# GD32A503 register map
File version: 1.0
GD32A503 ARM 32-bit Cortex-M33 Microcontroller based device
CPU: CM33 r0p4, little endian, MPU, FPU, 4 interrupt priority bits
Registers are 32-bit, read-write, reset 0x0 unless marked. A register's access mark holds for its fields unless they carry their own. Offsets are from the block's base; lines under a group give offsets from that group; [hi:lo] are bit positions; {n}, {i} and the like mark numbered series; 'fields as' and 'values as' point back to an identical list; <NAME> marks a mode.

## Memory map
0x40000000 TIMER1 size 0x400 — General-purpose-timers
0x40001000 TIMER5 size 0x400 — Basic-timers
0x40001400 TIMER6 size 0x400 — Basic-timers
0x40002800 RTC size 0x400 — Real-time clock
0x40002C00 WWDGT size 0x400 — Window watchdog timer
0x40003000 FWDGT size 0x400 — free watchdog timer
0x40003800 SPI1 size 0x400 — Serial peripheral interface
0x40004400 USART1 size 0x400
0x40004800 USART2 size 0x400
0x40005400 I2C0 size 0x400 — Inter integrated circuit
0x40005800 I2C1 size 0x400 — Inter integrated circuit
0x40006C00 BKP size 0x400 — Backup registers
0x40007000 PMU size 0x400 — Power management unit
0x40007400 DAC size 0x400 — Digital-to-analog converter
0x40010000 SYSCFG size 0x400 — System configuration controller
0x40010400 EXTI size 0x400 — External interrupt/event controller
0x40012400 ADC0 size 0x400 — Analog to digital converter
0x40012800 ADC1 size 0x400 — Analog to digital converter
0x40012C00 TIMER0 size 0x400 — Advanced-timers
0x40013000 SPI0 size 0x400 — Serial peripheral interface
0x40013400 TIMER7 size 0x400
0x40013800 USART0 size 0x400 — Universal synchronous asynchronous receiver transmitter
0x40015000 TIMER19 size 0x400 — Advanced-timers
0x40015400 TIMER20 size 0x400
0x40017C00 CMP size 0x400 — Comparator
0x40018400 TRIGSEL size 0x400 — Trigger selection controller
0x4001A000 CAN0 size 0x1000 — Controller area network
0x4001B000 CAN1 size 0x1000
0x40020000 DMA0 size 0x400 — DMA0 controller
0x40020400 DMA1 size 0x400 — DMA controller
0x40020800 DMAMUX size 0x400 — DMAMUX controller
0x40021000 RCU size 0x400 — Reset and clock unit
0x40022000 FMC size 0x400
0x40023000 CRC size 0x400 — cyclic redundancy check calculation unit
0x40038400 MFCOM size 0x800 — Multi-function communication Interface
0x48000000 GPIOA size 0x400 — General-purpose I/Os
0x48000400 GPIOB size 0x400 — General-purpose I/Os
0x48000800 GPIOC size 0x400
0x48000C00 GPIOD size 0x400
0x48001000 GPIOE size 0x400
0x48001400 GPIOF size 0x400
0xE000E100 NVIC size 0xF00 — Nested Vectored Interrupt Controller
0xE0044000 DBG size 0x400 — Debug support

## Interrupts
0 WWDGT
1 LVD (EXTI)
3 RTC
4 FMC
5 RCU
6 EXTI0 (EXTI)
7 EXTI1 (EXTI)
8 EXTI2 (EXTI)
9 EXTI3 (EXTI)
10 EXTI4 (EXTI)
11 DMA0_Channel0 (DMA0)
12 DMA0_Channel1 (DMA0)
13 DMA0_Channel2 (DMA0)
14 DMA0_Channel3 (DMA0)
15 DMA0_Channel4 (DMA0)
16 DMA0_Channel5 (DMA0)
17 DMA0_Channel6 (DMA0)
18 ADC (ADC0, ADC1)
19 CAN0_MF (CAN0)
20 CAN0_BUSOFF (CAN0)
21 CAN0_ER (CAN0)
22 CAN0_ERFT (CAN0)
23 CAN0_TW (CAN0)
24 CAN0_RW (CAN0)
25 CAN0_WAKE (CAN0)
26 TIMER0_BRK_UP_TR_CM (TIMER0)
27 TIMER0_CAP (TIMER0)
28 TIMER1
29 TIMER19_BRK_UP_TR_CM (TIMER19)
30 TIMER19_CAP (TIMER19)
31 I2C0_EV (I2C0)
32 I2C0_ER (I2C0)
33 I2C1_EV (I2C1)
34 I2C1_ER (I2C1)
35 SPI0
36 SPI1
37 USART0
38 USART1
39 USART2
40 EXTI10_15 (EXTI)
41 EXTI5_9 (EXTI)
42 Tamper (BKP)
43 TIMER20_BRK_UP_TR_CM (TIMER20)
44 TIMER20_CAP (TIMER20)
45 TIMER7_BRK_UP_TR_CM (TIMER7)
46 TIMER7_CAP (TIMER7)
47 DMA_MUX (DMAMUX)
49 CMP
51 OVD (EXTI)
54 TIMER5_DAC (DAC, TIMER5)
55 TIMER6
56 DMA1_Channel0 (DMA1)
57 DMA1_Channel1 (DMA1)
58 DMA1_Channel2 (DMA1)
59 DMA1_Channel3 (DMA1)
60 DMA1_Channel4 (DMA1)
62 CAN1_WAKE (CAN1)
63 CAN1_MF (CAN1)
64 CAN1_BUSOFF (CAN1)
65 CAN1_ER (CAN1)
66 CAN1_ERFT (CAN1)
67 CAN1_TW (CAN1)
68 CAN1_RW (CAN1)
70 MFCOM

## DAC — Digital-to-analog converter
Base 0x40007400
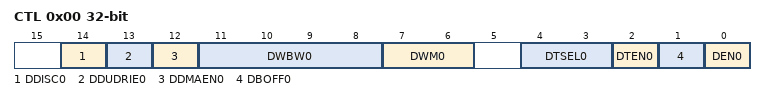
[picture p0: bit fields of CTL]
0x00 CTL — Control register
  [14] DDISC0 — DACx_OUT0 connect GPIO selection
  [13] DDUDRIE0 — DAC_OUT DMA underrun interrupt enable
  [12] DDMAEN0 — DAC_OUT DMA enable
  [11:8] DWBW0 — DAC_OUT noise wave bit width
  [7:6] DWM0 — DAC_OUT noise wave mode
  [4:3] DTSEL0 — DAC_OUT trigger selection
  [2] DTEN0 — DAC_OUT trigger enable
  [1] DBOFF0 — DAC_OUT output buffer turn off
  [0] DEN0 — DAC_OUT enable
0x04 SWT wo — Software trigger register
  [0] SWTR0 — DAC_OUT software trigger, cleared by hardware
0x08 OUT0_R12DH — DAC_OUT 12-bit right-aligned data holding register
  [11:0] OUT0_DH — DAC_OUT 12-bit right-aligned data
0x0C OUT0_L12DH — DAC_OUT 12-bit left-aligned data holding register
  [15:4] OUT0_DH — DAC_OUT 12-bit left-aligned data
0x10 OUT0_R8DH — DAC_OUT 8-bit right-aligned data holding register
  [7:0] OUT0_DH — DAC_OUT 8-bit right-aligned data
0x14 OUT0_DO ro — DAC_OUT data output register
  [11:0] OUT0_DO — DAC_OUT data output
0x18 STAT0 — DAC Status register 0
  [13] DDUDR0 — DAC_OUT DMA underrun flag
